# NUC122_v1 register map
File version: 1.0
Registers are 32-bit, read-write, reset 0x0 unless marked. A register's access mark holds for its fields unless they carry their own. Offsets are from the block's base; [hi:lo] are bit positions; {n}, {i} and the like mark numbered series; 'fields as' and 'values as' point back to an identical list.

## GP — GPIO Register Map
Base 0x50004000
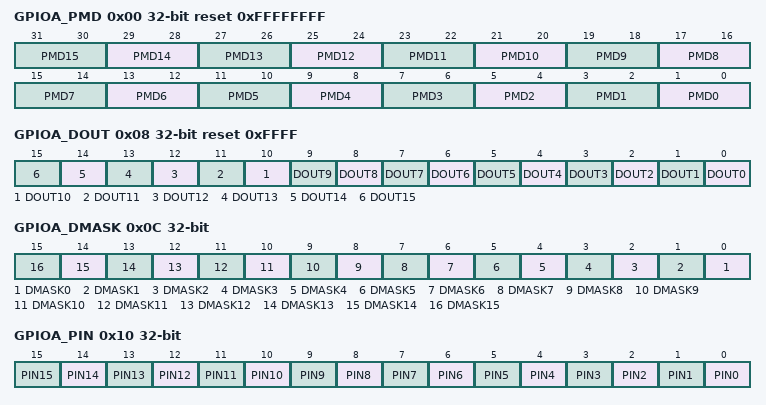
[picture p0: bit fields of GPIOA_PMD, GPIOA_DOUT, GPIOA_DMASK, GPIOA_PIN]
0x00 GPIOA_PMD reset 0xFFFFFFFF — GPIO Port A Pin I/O Mode Control
  [all] fields
    0=GPIO port [n] pin is in INPUT mode; 1=GPIO port [n] pin is in OUTPUT mode; 2=GPIO port [n] pin is in Open-Drain mode; 3=GPIO port [n] pin is in Quasi-bidirectional mode
  [2n+1:2n] PMD{n} (n=0..15) — GPIOx I/O Pin[n] Mode Control. Determine each I/O type of GPIOx pins.
0x04 GPIOA_OFFD — GPIO Port A Pin OFF Digital Enable
  [31:16] OFFD — GPIOx Pin[n] OFF Digital Input Path Enable. Each of these bits is used to control if the input path of corresponding GPIO pin is disabled. If input is analog signal, users can OFF digital input path to avoid creepage,
    0=Enable IO digital input path; 1=Disable IO digital input path (digital input tied to low)
0x08 GPIOA_DOUT reset 0xFFFF — GPIO Port A Data Output Value
  [all] fields
    0=GPIO port [A/B/C/D] Pin[n] will drive Low if the GPIO pin is configures as output, open-drain and quasi-bidirectional mode; 1=GPIO port [A/B/C/D] Pin[n] will drive High if the GPIO pin is configures as output, open-drain and quasi-bidirectional mode
  [n] DOUT{n} (n=0..15) — GPIOx Pin[n] Output Value. Each of these bits control the status of a GPIO pin when the GPIO pin is configures as output, open-drain and quasi-bidirectional mode.
0x0C GPIOA_DMASK — GPIO Port A Data Output Write Mask
  [all] fields
    0=The corresponding GPIOx_DOUT[n] bit can be updated; 1=The corresponding GPIOx_DOUT[n] bit is protected
  [n] DMASK{n} (n=0..15) — Port [A/B/C/D] Data Output Write Mask. These bits are used to protect the corresponding register of GPIOx_DOUT bit[n] . When set the DMASK bit[n] to 1, the corresponding GPIOx_DOUT[n] bit is protected. The write signal is masked, write data to the protect bit is ignored. Note: This function only protect corresponding GPIOx_DOUT[n] bit, and will not protect corresponding bit control register (GPIOAx_DOUT, GPIOBx_DOUT, GPIOCx_DOUT, GPIODx_DOUT).
0x10 GPIOA_PIN ro (reset mask 0xFFFF0000) — GPIO Port A Pin Value
  [n] PIN{n} (n=0..15) — Port [A/B/C/D] Pin Values. Each bit of the register reflects the actual status of the respective GPIO pin If bit is 1, it indicates the corresponding pin status is high, else the pin status is low
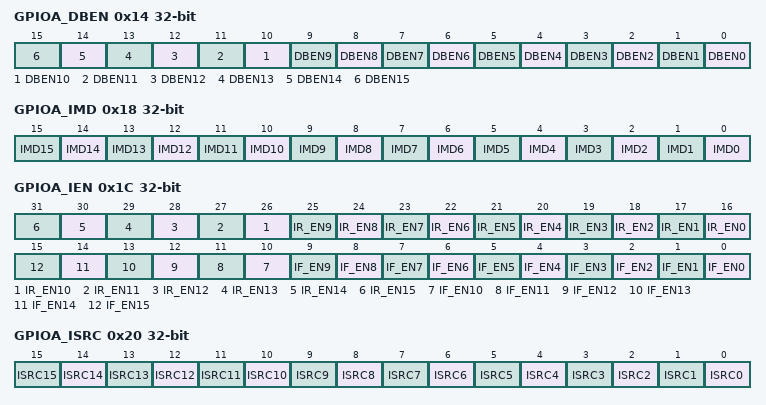
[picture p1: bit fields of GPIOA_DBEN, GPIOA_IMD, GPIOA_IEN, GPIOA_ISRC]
0x14 GPIOA_DBEN — GPIO Port A De-bounce Enable
  [all] fields
    0=The bit[n] de-bounce function is disabled; 1=The bit[n] de-bounce function is enabled
  [n] DBEN{n} (n=0..15) — Port [A/B/C/D] Input Signal De-bounce Enable. DBEN[n]used to enable the de-bounce function for each corresponding bit. If the input signal pulse width can't be sampled by continuous two de-bounce sample cycle The input signal transition is seen as the signal bounce and will not trigger the interrupt. The de-bounce clock source is controlled by DBNCECON[4], one de-bounce sample cycle is controlled by DBNCECON[3:0]. The de-bounce function is valid for edge triggered interrupt. If the interrupt mode is level triggered, the de-bounce enable bit is ignored.
0x18 GPIOA_IMD — GPIO Port A Interrupt Mode Control
  [all] fields
    0=Edge trigger interrupt; 1=Level trigger interrupt
  [n] IMD{n} (n=0..15) — Port [A/B/C/D] Edge or Level Detection Interrupt Control. IMD[n] is used to control the interrupt is by level trigger or by edge trigger. If the interrupt is by edge trigger, the trigger source can be controlled by de-bounce. If the interrupt is by level trigger, the input source is sampled by one HCLK clock and generates the interrupt. If set pin as the level trigger interrupt, then only one level can be set on the registers GPIOx_IEN. If set both the level to trigger interrupt, the setting is ignored and no interrupt will occur. The de-bounce function is valid for edge triggered interrupt. If the interrupt mode is level triggered, the de-bounce enable bit is ignored.
0x1C GPIOA_IEN — GPIO Port A Interrupt Enable
  [n+16] IR_EN{n} (n=0..15) — Port [A/B/C/D] Interrupt Enable by Input Rising Edge or Input Level High. IR_EN[n] used to enable the interrupt for each of the corresponding input GPIO_PIN[n]. Set bit to 1 also enable the pin wake-up function. When set the IR_EN[n] bit to 1: If the interrupt is level trigger, the input PIN[n] state at level "high" will generate the interrupt. If the interrupt is edge trigger, the input PIN[n] state change from "low-to-high" will generate the interrupt.
    0=Disable the PIN[n] level-high or low-to-high interrupt; 1=Enable the PIN[n] level-high or low-to-high interrupt
  [n] IF_EN{n} (n=0..15) — Port [A/B/C/D] Interrupt Enable by Input Falling Edge or Input Level Low. IF_EN[n] used to enable the interrupt for each of the corresponding input GPIO_PIN[n]. Set bit to 1 also enable the pin wake-up function. When set the IF_EN[n] bit to 1: If the interrupt is level trigger, the input PIN[n] state at level "low" will generate the interrupt. If the interrupt is edge trigger, the input PIN[n] state change from "high-to-low" will generate the interrupt.
    0=Disable the PIN[n] state low-level or high-to-low change interrupt; 1=Enable the PIN[n] state low-level or high-to-low change interrupt
0x20 GPIOA_ISRC — GPIO Port A Interrupt Trigger Source Indicator
  [all] fields
    0=No interrupt at GPIOx[n]. No action; 1=Indicates GPIOx[n] generate an interrupt. Clear the correspond pending interrupt
  [n] ISRC{n} (n=0..15) — Port [A/B/C/D] Interrupt Trigger Source Indicator. Read :
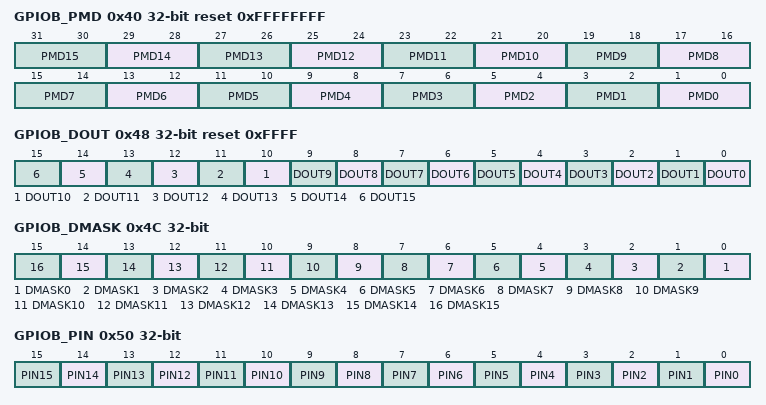
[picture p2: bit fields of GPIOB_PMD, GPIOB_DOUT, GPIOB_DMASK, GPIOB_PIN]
0x40 GPIOB_PMD reset 0xFFFFFFFF — GPIO Port B Pin I/O Mode Control
  fields as GPIOA_PMD
0x44 GPIOB_OFFD — GPIO Port B Pin OFF Digital Enable
  fields as GPIOA_OFFD
0x48 GPIOB_DOUT reset 0xFFFF — GPIO Port B Data Output Value
  fields as GPIOA_DOUT
0x4C GPIOB_DMASK — GPIO Port B Data Output Write Mask
  fields as GPIOA_DMASK
0x50 GPIOB_PIN ro (reset mask 0xFFFF0000) — GPIO Port B Pin Value
  fields as GPIOA_PIN
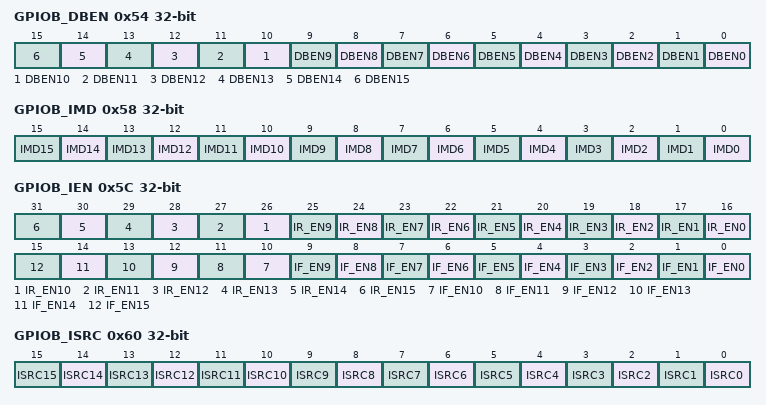
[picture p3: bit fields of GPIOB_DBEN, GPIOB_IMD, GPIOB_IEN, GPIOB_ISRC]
0x54 GPIOB_DBEN — GPIO Port B De-bounce Enable
  fields as GPIOA_DBEN
0x58 GPIOB_IMD — GPIO Port B Interrupt Mode Control
  fields as GPIOA_IMD
0x5C GPIOB_IEN — GPIO Port B Interrupt Enable
  fields as GPIOA_IEN
0x60 GPIOB_ISRC — GPIO Port B Interrupt Trigger Source Indicator
  fields as GPIOA_ISRC
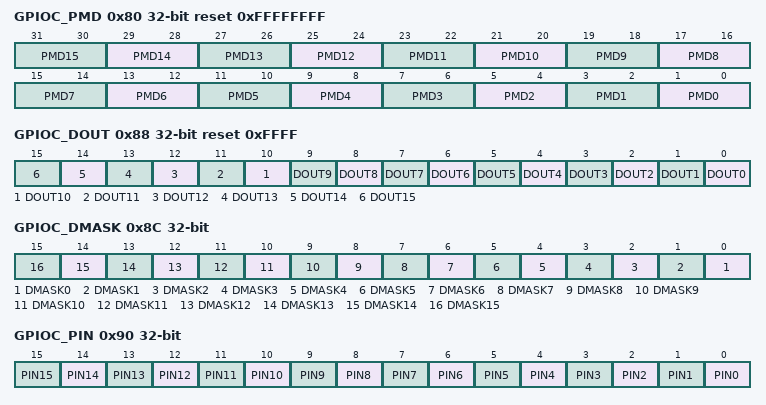
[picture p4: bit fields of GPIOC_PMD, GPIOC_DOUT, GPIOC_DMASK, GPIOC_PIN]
0x80 GPIOC_PMD reset 0xFFFFFFFF — GPIO Port C Pin I/O Mode Control
  fields as GPIOA_PMD
0x84 GPIOC_OFFD — GPIO Port C Pin OFF Digital Enable
  fields as GPIOA_OFFD
0x88 GPIOC_DOUT reset 0xFFFF — GPIO Port C Data Output Value
  fields as GPIOA_DOUT
0x8C GPIOC_DMASK — GPIO Port C Data Output Write Mask
  fields as GPIOA_DMASK
0x90 GPIOC_PIN ro (reset mask 0xFFFF0000) — GPIO Port C Pin Value
  fields as GPIOA_PIN
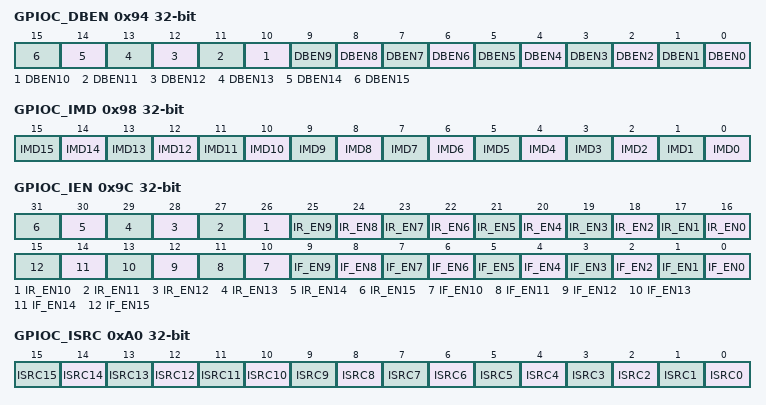
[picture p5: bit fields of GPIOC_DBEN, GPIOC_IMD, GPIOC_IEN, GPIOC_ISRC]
0x94 GPIOC_DBEN — GPIO Port C De-bounce Enable
  fields as GPIOA_DBEN
0x98 GPIOC_IMD — GPIO Port C Interrupt Mode Control
  fields as GPIOA_IMD
0x9C GPIOC_IEN — GPIO Port C Interrupt Enable
  fields as GPIOA_IEN
0xA0 GPIOC_ISRC — GPIO Port C Interrupt Trigger Source Indicator
  fields as GPIOA_ISRC
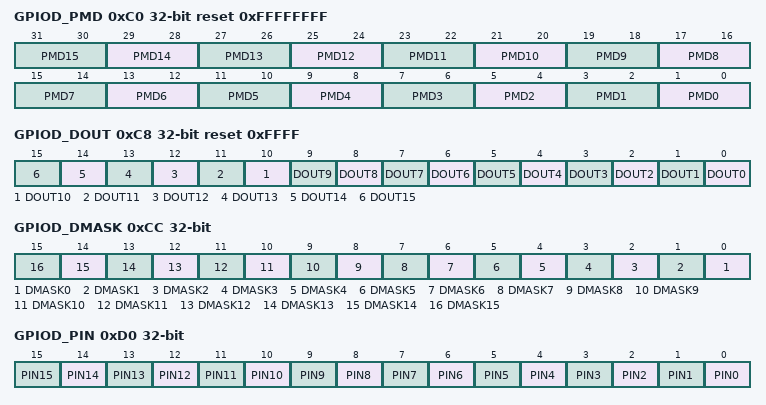
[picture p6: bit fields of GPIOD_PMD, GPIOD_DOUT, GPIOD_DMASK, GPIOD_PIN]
0xC0 GPIOD_PMD reset 0xFFFFFFFF — GPIO Port D Pin I/O Mode Control
  fields as GPIOA_PMD
0xC4 GPIOD_OFFD — GPIO Port D Pin OFF Digital Enable
  fields as GPIOA_OFFD
0xC8 GPIOD_DOUT reset 0xFFFF — GPIO Port D Data Output Value
  fields as GPIOA_DOUT
0xCC GPIOD_DMASK — GPIO Port D Data Output Write Mask
  fields as GPIOA_DMASK
0xD0 GPIOD_PIN ro (reset mask 0xFFFF0000) — GPIO Port D Pin Value
  fields as GPIOA_PIN
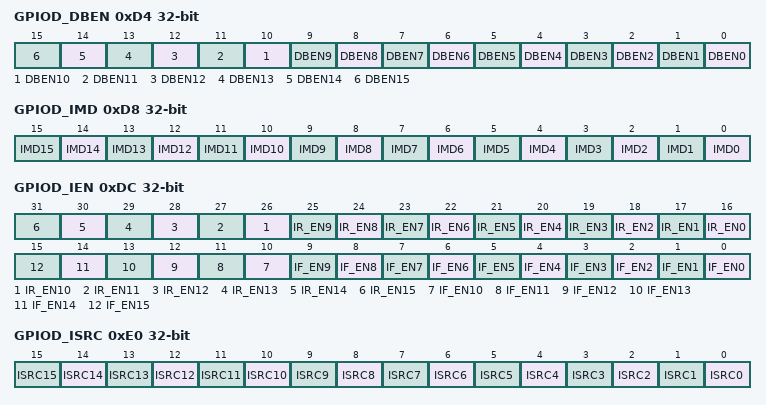
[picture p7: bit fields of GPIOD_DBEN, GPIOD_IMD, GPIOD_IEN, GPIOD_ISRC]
0xD4 GPIOD_DBEN — GPIO Port D De-bounce Enable
  fields as GPIOA_DBEN
0xD8 GPIOD_IMD — GPIO Port D Interrupt Mode Control
  fields as GPIOA_IMD
0xDC GPIOD_IEN — GPIO Port D Interrupt Enable
  fields as GPIOA_IEN
0xE0 GPIOD_ISRC — GPIO Port D Interrupt Trigger Source Indicator
  fields as GPIOA_ISRC
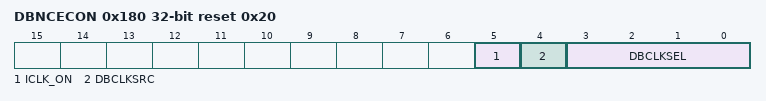
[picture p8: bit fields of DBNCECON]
0x180 DBNCECON reset 0x20 — De-bounce Cycle Control
  [5] ICLK_ON — Interrupt Clock On Mode. Set this bit to 0 will disable the interrupt generate circuit clock, if the pin[n] interrupt is disabled
    0=Disable the clock if the GPIOA/B/C/D[n] interrupt is disabled; 1=Interrupt generated circuit clock always enable
  [4] DBCLKSRC — De-bounce Counter Clock Source Selection
    0=De-bounce counter clock source is the HCLK; 1=De-bounce counter clock source is the internal 10 KHz low speed clock
  [3:0] DBCLKSEL — De-bounce Sampling Cycle Selection
0x200 GPIOA0_DOUT (reset mask 0xFFFFFFF0) — GPIO PA.0 Bit Output/Input Value
  [0] GPIOxx_DOUT — GPIOxx I/O Pin Bit Output/Input Control. Write this bit can control one GPIO pin output value. Read this register to get IO pin status. For example: write GPIOA0_DOUT will reflect the written value to bit GPIOA_DOUT[0], read GPIOA0_DOUT will return the value of GPIOA_PIN[0].
    0=Set corresponding GPIO pin to low; 1=Set corresponding GPIO pin to high
0x204 GPIOA1_DOUT (reset mask 0xFFFFFFF0) — GPIO PA.1 Bit Output/Input Value
  fields as GPIOA0_DOUT
0x208 GPIOA2_DOUT (reset mask 0xFFFFFFF0) — GPIO PA.2 Bit Output/Input Value
  fields as GPIOA0_DOUT
0x20C GPIOA3_DOUT (reset mask 0xFFFFFFF0) — GPIO PA.3 Bit Output/Input Value
  fields as GPIOA0_DOUT
0x210 GPIOA4_DOUT (reset mask 0xFFFFFFF0) — GPIO PA.4 Bit Output/Input Value
  fields as GPIOA0_DOUT
0x214 GPIOA5_DOUT (reset mask 0xFFFFFFF0) — GPIO PA.5 Bit Output/Input Value
  fields as GPIOA0_DOUT
0x218 GPIOA6_DOUT (reset mask 0xFFFFFFF0) — GPIO PA.6 Bit Output/Input Value
  fields as GPIOA0_DOUT
0x21C GPIOA7_DOUT (reset mask 0xFFFFFFF0) — GPIO PA.7 Bit Output/Input Value
  fields as GPIOA0_DOUT
0x220 GPIOA8_DOUT (reset mask 0xFFFFFFF0) — GPIO PA.8 Bit Output/Input Value
  fields as GPIOA0_DOUT
0x224 GPIOA9_DOUT (reset mask 0xFFFFFFF0) — GPIO PA.9 Bit Output/Input Value
  fields as GPIOA0_DOUT
0x228 GPIOA10_DOUT (reset mask 0xFFFFFFF0) — GPIO PA.10 Bit Output/Input Value
  fields as GPIOA0_DOUT
0x22C GPIOA11_DOUT (reset mask 0xFFFFFFF0) — GPIO PA.11 Bit Output/Input Value
  fields as GPIOA0_DOUT
0x230 GPIOA12_DOUT (reset mask 0xFFFFFFF0) — GPIO PA.12 Bit Output/Input Value
  fields as GPIOA0_DOUT
0x234 GPIOA13_DOUT (reset mask 0xFFFFFFF0) — GPIO PA.13 Bit Output/Input Value
  fields as GPIOA0_DOUT
0x238 GPIOA14_DOUT (reset mask 0xFFFFFFF0) — GPIO PA.14 Bit Output/Input Value
  fields as GPIOA0_DOUT
0x23C GPIOA15_DOUT (reset mask 0xFFFFFFF0) — GPIO PA.15 Bit Output/Input Value
  fields as GPIOA0_DOUT
0x240 GPIOB0_DOUT (reset mask 0xFFFFFFF0) — GPIO PB.0 Bit Output/Input Value
  fields as GPIOA0_DOUT
0x244 GPIOB1_DOUT (reset mask 0xFFFFFFF0) — GPIO PB.1 Bit Output/Input Value
  fields as GPIOA0_DOUT
0x248 GPIOB2_DOUT (reset mask 0xFFFFFFF0) — GPIO PB.2 Bit Output/Input Value
  fields as GPIOA0_DOUT
0x24C GPIOB3_DOUT (reset mask 0xFFFFFFF0) — GPIO PB.3 Bit Output/Input Value
  fields as GPIOA0_DOUT
0x250 GPIOB4_DOUT (reset mask 0xFFFFFFF0) — GPIO PB.4 Bit Output/Input Value
  fields as GPIOA0_DOUT
0x254 GPIOB5_DOUT (reset mask 0xFFFFFFF0) — GPIO PB.5 Bit Output/Input Value
  fields as GPIOA0_DOUT
0x258 GPIOB6_DOUT (reset mask 0xFFFFFFF0) — GPIO PB.6 Bit Output/Input Value
  fields as GPIOA0_DOUT
0x25C GPIOB7_DOUT (reset mask 0xFFFFFFF0) — GPIO PB.7 Bit Output/Input Value
  fields as GPIOA0_DOUT
0x260 GPIOB8_DOUT (reset mask 0xFFFFFFF0) — GPIO PB.8 Bit Output/Input Value
  fields as GPIOA0_DOUT
0x264 GPIOB9_DOUT (reset mask 0xFFFFFFF0) — GPIO PB.9 Bit Output/Input Value
  fields as GPIOA0_DOUT
0x268 GPIOB10_DOUT (reset mask 0xFFFFFFF0) — GPIO PB.10 Bit Output/Input Value
  fields as GPIOA0_DOUT
0x26C GPIOB11_DOUT (reset mask 0xFFFFFFF0) — GPIO PB.11 Bit Output/Input Value
  fields as GPIOA0_DOUT
0x270 GPIOB12_DOUT (reset mask 0xFFFFFFF0) — GPIO PB.12 Bit Output/Input Value
  fields as GPIOA0_DOUT
0x274 GPIOB13_DOUT (reset mask 0xFFFFFFF0) — GPIO PB.13 Bit Output/Input Value
  fields as GPIOA0_DOUT
0x278 GPIOB14_DOUT (reset mask 0xFFFFFFF0) — GPIO PB.14 Bit Output/Input Value
  fields as GPIOA0_DOUT
0x27C GPIOB15_DOUT (reset mask 0xFFFFFFF0) — GPIO PB.15 Bit Output/Input Value
  fields as GPIOA0_DOUT
0x280 GPIOC0_DOUT (reset mask 0xFFFFFFF0) — GPIO PC.0 Bit Output/Input Value
  fields as GPIOA0_DOUT
0x284 GPIOC1_DOUT (reset mask 0xFFFFFFF0) — GPIO PC.1 Bit Output/Input Value
  fields as GPIOA0_DOUT
0x288 GPIOC2_DOUT (reset mask 0xFFFFFFF0) — GPIO PC.2 Bit Output/Input Value
  fields as GPIOA0_DOUT
0x28C GPIOC3_DOUT (reset mask 0xFFFFFFF0) — GPIO PC.3 Bit Output/Input Value
  fields as GPIOA0_DOUT
0x290 GPIOC4_DOUT (reset mask 0xFFFFFFF0) — GPIO PC.4 Bit Output/Input Value
  fields as GPIOA0_DOUT
0x294 GPIOC5_DOUT (reset mask 0xFFFFFFF0) — GPIO PC.5 Bit Output/Input Value
  fields as GPIOA0_DOUT
0x298 GPIOC6_DOUT (reset mask 0xFFFFFFF0) — GPIO PC.6 Bit Output/Input Value
  fields as GPIOA0_DOUT
0x29C GPIOC7_DOUT (reset mask 0xFFFFFFF0) — GPIO PC.7 Bit Output/Input Value
  fields as GPIOA0_DOUT
0x2A0 GPIOC8_DOUT (reset mask 0xFFFFFFF0) — GPIO PC.8 Bit Output/Input Value
  fields as GPIOA0_DOUT
0x2A4 GPIOC9_DOUT (reset mask 0xFFFFFFF0) — GPIO PC.9 Bit Output/Input Value
  fields as GPIOA0_DOUT
0x2A8 GPIOC10_DOUT (reset mask 0xFFFFFFF0) — GPIO PC.10 Bit Output/Input Value
  fields as GPIOA0_DOUT
0x2AC GPIOC11_DOUT (reset mask 0xFFFFFFF0) — GPIO PC.11 Bit Output/Input Value
  fields as GPIOA0_DOUT
0x2B0 GPIOC12_DOUT (reset mask 0xFFFFFFF0) — GPIO PC.12 Bit Output/Input Value
  fields as GPIOA0_DOUT
0x2B4 GPIOC13_DOUT (reset mask 0xFFFFFFF0) — GPIO PC.13 Bit Output/Input Value
  fields as GPIOA0_DOUT
0x2B8 GPIOC14_DOUT (reset mask 0xFFFFFFF0) — GPIO PC.14 Bit Output/Input Value
  fields as GPIOA0_DOUT
0x2BC GPIOC15_DOUT (reset mask 0xFFFFFFF0) — GPIO PC.15 Bit Output/Input Value
  fields as GPIOA0_DOUT
0x2C0 GPIOD0_DOUT (reset mask 0xFFFFFFF0) — GPIO PD.0 Bit Output/Input Value
  fields as GPIOA0_DOUT
0x2C4 GPIOD1_DOUT (reset mask 0xFFFFFFF0) — GPIO PD.1 Bit Output/Input Value
  fields as GPIOA0_DOUT
0x2C8 GPIOD2_DOUT (reset mask 0xFFFFFFF0) — GPIO PD.2 Bit Output/Input Value
  fields as GPIOA0_DOUT
0x2CC GPIOD3_DOUT (reset mask 0xFFFFFFF0) — GPIO PD.3 Bit Output/Input Value
  fields as GPIOA0_DOUT
0x2D0 GPIOD4_DOUT (reset mask 0xFFFFFFF0) — GPIO PD.4 Bit Output/Input Value
  fields as GPIOA0_DOUT
0x2D4 GPIOD5_DOUT (reset mask 0xFFFFFFF0) — GPIO PD.5 Bit Output/Input Value
  fields as GPIOA0_DOUT
0x2D8 GPIOD6_DOUT (reset mask 0xFFFFFFF0) — GPIO PD.6 Bit Output/Input Value
  fields as GPIOA0_DOUT
0x2DC GPIOD7_DOUT (reset mask 0xFFFFFFF0) — GPIO PD.7 Bit Output/Input Value
  fields as GPIOA0_DOUT
0x2E0 GPIOD8_DOUT (reset mask 0xFFFFFFF0) — GPIO PD.8 Bit Output/Input Value
  fields as GPIOA0_DOUT
0x2E4 GPIOD9_DOUT (reset mask 0xFFFFFFF0) — GPIO PD.9 Bit Output/Input Value
  fields as GPIOA0_DOUT
0x2E8 GPIOD10_DOUT (reset mask 0xFFFFFFF0) — GPIO PD.10 Bit Output/Input Value
  fields as GPIOA0_DOUT
0x2EC GPIOD11_DOUT (reset mask 0xFFFFFFF0) — GPIO PD.11 Bit Output/Input Value
  fields as GPIOA0_DOUT
0x2F0 GPIOD12_DOUT (reset mask 0xFFFFFFF0) — GPIO PD.12 Bit Output/Input Value
  fields as GPIOA0_DOUT
0x2F4 GPIOD13_DOUT (reset mask 0xFFFFFFF0) — GPIO PD.13 Bit Output/Input Value
  fields as GPIOA0_DOUT
0x2F8 GPIOD14_DOUT (reset mask 0xFFFFFFF0) — GPIO PD.14 Bit Output/Input Value
  fields as GPIOA0_DOUT
0x2FC GPIOD15_DOUT (reset mask 0xFFFFFFF0) — GPIO PD.15 Bit Output/Input Value
  fields as GPIOA0_DOUT
